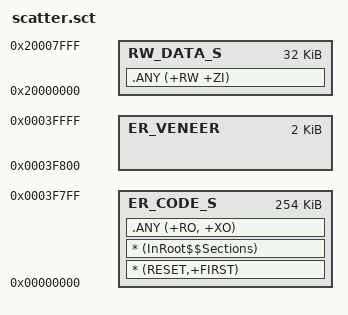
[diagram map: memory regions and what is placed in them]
LR_CODE_S 0x0 0x3F800 {
  ER_CODE_S 0x0 0x3F800 {
  	* (RESET,+FIRST)
    * (InRoot$$Sections)
    .ANY (+RO, +XO)
  }
  RW_DATA_S 0x20000000 0x8000 {
    .ANY (+RW +ZI)
  }
}
LR_VENEER 0x3F800 0x800 {
  ER_VENEER 0x3F800 0x800 {
  }
}
